# RA6M2 register map
Vendor: Renesas Electronics Corporation; Series: RA6; File version: 1.1
CPU: CM4 r0p1, little endian, MPU, FPU, VTOR, 4 interrupt priority bits
Registers are 8-bit, read-write, reset 0x0 unless marked. A register's access mark holds for its fields unless they carry their own. Offsets are from the block's base; [hi:lo] are bit positions; {n}, {i} and the like mark numbered series; 'fields as' and 'values as' point back to an identical list; <NAME> marks a mode.

## GPT32EH0 (part 2 of 2) — General PWM Timer 0 (32-bit Enhanced High Resolution)
Base 0x40078000
Same registers: GPT32EH1 0x40078100, GPT32EH2 0x40078200, GPT32EH3 0x40078300, GPT32E4 0x40078400, GPT32E5 0x40078500, GPT32E6 0x40078600, GPT32E7 0x40078700
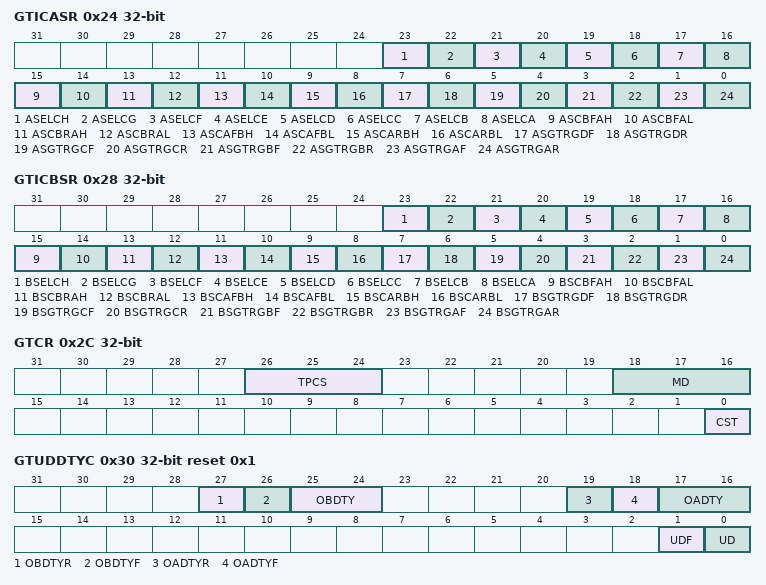
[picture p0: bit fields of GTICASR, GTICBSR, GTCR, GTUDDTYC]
0x24 GTICASR 32-bit — General PWM Timer Input Capture Source Select Register A
  [23] ASELCH — ELC_GPTH Event Source GTCCRA Input Capture Enable
    0=Disable GTCCRA input capture on ELC_GPTH input; 1=Enable GTCCRA input capture on ELC_GPTH input
  [22] ASELCG — ELC_GPTG Event Source GTCCRA Input Capture Enable
    0=Disable GTCCRA input capture on ELC_GPTG input; 1=Enable GTCCRA input capture on ELC_GPTG input
  [21] ASELCF — ELC_GPTF Event Source GTCCRA Input Capture Enable
    0=Disable GTCCRA input capture on ELC_GPTF input; 1=Enable GTCCRA input capture on ELC_GPTF input
  [20] ASELCE — ELC_GPTE Event Source GTCCRA Input Capture Enable
    0=Disable GTCCRA input capture on ELC_GPTE input; 1=Enable GTCCRA input capture on ELC_GPTE input
  [19] ASELCD — ELC_GPTD Event Source GTCCRA Input Capture Enable
    0=Disable GTCCRA input capture on ELC_GPTD input; 1=Enable GTCCRA input capture on ELC_GPTD input
  [18] ASELCC — ELC_GPTC Event Source GTCCRA Input Capture Enable
    0=Disable GTCCRA input capture on ELC_GPTC input; 1=Enable GTCCRA input capture on ELC_GPTC input
  [17] ASELCB — ELC_GPTB Event Source GTCCRA Input Capture Enable
    0=Disable GTCCRA input capture on ELC_GPTB input; 1=Enable GTCCRA input capture on ELC_GPTB input
  [16] ASELCA — ELC_GPTA Event Source GTCCRA Input Capture Enable
    0=Disable GTCCRA input capture on ELC_GPTA input; 1=Enable GTCCRA input capture on ELC_GPTA input
  [15] ASCBFAH — GTIOCB Pin Falling Input during GTIOCA Value High Source GTCCRA Input Capture Enable
    0=Disable GTCCRA input capture on the falling edge of GTIOCB input when GTIOCA input is 1; 1=Enable GTCCRA input capture on the falling edge of GTIOCB input when GTIOCA input is 1
  [14] ASCBFAL — GTIOCB Pin Falling Input during GTIOCA Value Low Source GTCCRA Input Capture Enable
    0=Disable GTCCRA input capture on the falling edge of GTIOCB input when GTIOCA input is 0; 1=Enable GTCCRA input capture on the falling edge of GTIOCB input when GTIOCA input is 0
  [13] ASCBRAH — GTIOCB Pin Rising Input during GTIOCA Value High Source GTCCRA Input Capture Enable
    0=Disable GTCCRA input capture on the rising edge of GTIOCB input when GTIOCA input is 1; 1=Enable GTCCRA input capture on the rising edge of GTIOCB input when GTIOCA input is 1
  [12] ASCBRAL — GTIOCB Pin Rising Input during GTIOCA Value Low Source GTCCRA Input Capture Enable
    0=Disable GTCCRA input capture on the rising edge of GTIOCB input when GTIOCA input is 0; 1=Enable GTCCRA input capture on the rising edge of GTIOCB input when GTIOCA input is 0
  [11] ASCAFBH — GTIOCA Pin Falling Input during GTIOCB Value High Source GTCCRA Input Capture Enable
    0=Disable GTCCRA input capture on the falling edge of GTIOCA input when GTIOCB input is 1; 1=Enable GTCCRA input capture on the falling edge of GTIOCA input when GTIOCB input is 1
  [10] ASCAFBL — GTIOCA Pin Falling Input during GTIOCB Value Low Source GTCCRA Input Capture Enable
    0=Disable GTCCRA input capture on the falling edge of GTIOCA input when GTIOCB input is 0; 1=Enable GTCCRA input capture on the falling edge of GTIOCA input when GTIOCB input is 0
  [9] ASCARBH — GTIOCA Pin Rising Input during GTIOCB Value High Source GTCCRA Input Capture Enable
    0=Disable GTCCRA input capture on the rising edge of GTIOCA input when GTIOCB input is 1; 1=Enable GTCCRA input capture on the rising edge of GTIOCA input when GTIOCB input is 1
  [8] ASCARBL — GTIOCA Pin Rising Input during GTIOCB Value Low Source GTCCRA Input Capture Enable
    0=Disable GTCCRA input capture on the rising edge of GTIOCA input when GTIOCB input is 0; 1=Enable GTCCRA input capture on the rising edge of GTIOCA input when GTIOCB input is 0
  [7] ASGTRGDF — GTETRGD Pin Falling Input Source GTCCRA Input Capture Enable
    0=Disable GTCCRA input capture on the falling edge of GTETRGD input; 1=Enable GTCCRA input capture on the falling edge of GTETRGD input
  [6] ASGTRGDR — GTETRGD Pin Rising Input Source GTCCRA Input Capture Enable
    0=Disable GTCCRA input capture on the rising edge of GTETRGD input; 1=Enable GTCCRA input capture on the rising edge of GTETRGD input
  [5] ASGTRGCF — GTETRGC Pin Falling Input Source GTCCRA Input Capture Enable
    0=Disable GTCCRA input capture on the falling edge of GTETRGC input; 1=Enable GTCCRA input capture on the falling edge of GTETRGC input
  [4] ASGTRGCR — GTETRGC Pin Rising Input Source GTCCRA Input Capture Enable
    0=Disable GTCCRA input capture on the rising edge of GTETRGC input; 1=Enable GTCCRA input capture on the rising edge of GTETRGC input
  [3] ASGTRGBF — GTETRGB Pin Falling Input Source GTCCRA Input Capture Enable
    0=Disable GTCCRA input capture on the falling edge of GTETRGB input; 1=Enable GTCCRA input capture on the falling edge of GTETRGB input
  [2] ASGTRGBR — GTETRGB Pin Rising Input Source GTCCRA Input Capture Enable
    0=Disable GTCCRA input capture on the rising edge of GTETRGB input; 1=Enable GTCCRA input capture on the rising edge of GTETRGB input
  [1] ASGTRGAF — GTETRGA Pin Falling Input Source GTCCRA Input Capture Enable
    0=Disable GTCCRA input capture on the falling edge of GTETRGA input; 1=Enable GTCCRA input capture on the falling edge of GTETRGA input
  [0] ASGTRGAR — GTETRGA Pin Rising Input Source GTCCRA Input Capture Enable
    0=Disable GTCCRA input capture on the rising edge of GTETRGA input; 1=Enable GTCCRA input capture on the rising edge of GTETRGA input
0x28 GTICBSR 32-bit — General PWM Timer Input Capture Source Select Register B
  [23] BSELCH — ELC_GPTH Event Source GTCCRB Input Capture Enable
    0=Disable GTCCRB input capture on ELC_GPTH input; 1=Enable GTCCRB input capture on ELC_GPTH input
  [22] BSELCG — ELC_GPTG Event Source GTCCRB Input Capture Enable
    0=Disable GTCCRB input capture on ELC_GPTG input; 1=Enable GTCCRB input capture on ELC_GPTG input
  [21] BSELCF — ELC_GPTF Event Source GTCCRB Input Capture Enable
    0=Disable GTCCRB input capture on ELC_GPTF input; 1=Enable GTCCRB input capture on ELC_GPTF input
  [20] BSELCE — ELC_GPTE Event Source GTCCRB Input Capture Enable
    0=Disable GTCCRB input capture on ELC_GPTE input; 1=Enable GTCCRB input capture on ELC_GPTE input
  [19] BSELCD — ELC_GPTD Event Source GTCCRB Input Capture Enable
    0=Disable GTCCRB input capture on ELC_GPTD input; 1=Enable GTCCRB input capture on ELC_GPTD input
  [18] BSELCC — ELC_GPTC Event Source GTCCRB Input Capture Enable
    0=Disable GTCCRB input capture on ELC_GPTC input; 1=Enable GTCCRB input capture on ELC_GPTC input
  [17] BSELCB — ELC_GPTB Event Source GTCCRB Input Capture Enable
    0=Disable GTCCRB input capture on ELC_GPTB input; 1=Enable GTCCRB input capture on ELC_GPTB input
  [16] BSELCA — ELC_GPTA Event Source GTCCRB Input Capture Enable
    0=Disable GTCCRB input capture on ELC_GPTA input; 1=Enable GTCCRB input capture on ELC_GPTA input
  [15] BSCBFAH — GTIOCB Pin Falling Input during GTIOCA Value High Source GTCCRB Input Capture Enable
    0=Disable GTCCRB input capture on the falling edge of GTIOCB input when GTIOCA input is 1; 1=Enable GTCCRB input capture on the falling edge of GTIOCB input when GTIOCA input is 1
  [14] BSCBFAL — GTIOCB Pin Falling Input during GTIOCA Value Low Source GTCCRB Input Capture Enable
    0=Disable GTCCRB input capture on the falling edge of GTIOCB input when GTIOCA input is 0; 1=Enable GTCCRB input capture on the falling edge of GTIOCB input when GTIOCA input is 0
  [13] BSCBRAH — GTIOCB Pin Rising Input during GTIOCA Value High Source GTCCRB Input Capture Enable
    0=Disable GTCCRB input capture on the rising edge of GTIOCB input when GTIOCA input is 1; 1=Enable GTCCRB input capture on the rising edge of GTIOCB input when GTIOCA input is 1
  [12] BSCBRAL — GTIOCB Pin Rising Input during GTIOCA Value Low Source GTCCRB Input Capture Enable
    0=Disable GTCCRB input capture on the rising edge of GTIOCB input when GTIOCA input is 0; 1=Enable GTCCRB input capture on the rising edge of GTIOCB input when GTIOCA input is 0
  [11] BSCAFBH — GTIOCA Pin Falling Input during GTIOCB Value High Source GTCCRB Input Capture Enable
    0=Disable GTCCRB input capture on the falling edge of GTIOCA input when GTIOCB input is 1; 1=Enable GTCCRB input capture on the falling edge of GTIOCA input when GTIOCB input is 1
  [10] BSCAFBL — GTIOCA Pin Falling Input during GTIOCB Value Low Source GTCCRB Input Capture Enable
    0=Disable GTCCRB input capture on the falling edge of GTIOCA input when GTIOCB input is 0; 1=Enable GTCCRB input capture on the falling edge of GTIOCA input when GTIOCB input is 0
  [9] BSCARBH — GTIOCA Pin Rising Input during GTIOCB Value High Source GTCCRB Input Capture Enable
    0=Disable GTCCRB input capture on the rising edge of GTIOCA input when GTIOCB input is 1; 1=Enable GTCCRB input capture on the rising edge of GTIOCA input when GTIOCB input is 1
  [8] BSCARBL — GTIOCA Pin Rising Input during GTIOCB Value Low Source GTCCRB Input Capture Enable
    0=Disable GTCCRB input capture on the rising edge of GTIOCA input when GTIOCB input is 0; 1=Enable GTCCRB input capture on the rising edge of GTIOCA input when GTIOCB input is 0
  [7] BSGTRGDF — GTETRGD Pin Falling Input Source GTCCRB Input Capture Enable
    0=Disable GTCCRB input capture on the falling edge of GTETRGD input; 1=Enable GTCCRB input capture on the falling edge of GTETRGD input
  [6] BSGTRGDR — GTETRGD Pin Rising Input Source GTCCRB Input Capture Enable
    0=Disable GTCCRB input capture on the rising edge of GTETRGD input; 1=Enable GTCCRB input capture on the rising edge of GTETRGD input
  [5] BSGTRGCF — GTETRGC Pin Falling Input Source GTCCRB Input Capture Enable
    0=Disable GTCCRB input capture on the falling edge of GTETRGC input; 1=Enable GTCCRB input capture on the falling edge of GTETRGC input
  [4] BSGTRGCR — GTETRGC Pin Rising Input Source GTCCRB Input Capture Enable
    0=Disable GTCCRB input capture on the rising edge of GTETRGC input; 1=Enable GTCCRB input capture on the rising edge of GTETRGC input
  [3] BSGTRGBF — GTETRGB Pin Falling Input Source GTCCRB Input Capture Enable
    0=Disable GTCCRB input capture on the falling edge of GTETRGB input; 1=Enable GTCCRB input capture on the falling edge of GTETRGB input
  [2] BSGTRGBR — GTETRGB Pin Rising Input Source GTCCRB Input Capture Enable
    0=Disable GTCCRB input capture on the rising edge of GTETRGB input; 1=Enable GTCCRB input capture on the rising edge of GTETRGB input
  [1] BSGTRGAF — GTETRGA Pin Falling Input Source GTCCRB Input Capture Enable
    0=Disable GTCCRB input capture on the falling edge of GTETRGA input; 1=Enable GTCCRB input capture on the falling edge of GTETRGA input
  [0] BSGTRGAR — GTETRGA Pin Rising Input Source GTCCRB Input Capture Enable
    0=Disable GTCCRB input capture on the rising edge of GTETRGA input; 1=Enable GTCCRB input capture on the rising edge of GTETRGA input
0x2C GTCR 32-bit — General PWM Timer Control Register
  [26:24] TPCS — Timer Prescaler Select
    0=PCLK/1; 1=PCLK/4; 2=PCLK/16; 3=PCLK/64; 4=PCLK/256; 5=PCLK/1024; other=others (Setting prohibited)
  [18:16] MD — Mode Select
    0=Saw-wave PWM mode (single buffer or double buffer possible); 1=Saw-wave one-shot pulse mode (fixed buffer operation); 2=Setting prohibited; 3=Setting prohibited; 4=Triangle-wave PWM mode 1 (32-bit transfer at crest) (single buffer or double buffer possible); 5=Triangle-wave PWM mode 2 (32-bit transfer at crest and trough) (single buffer or double buffer possible); 6=Triangle-wave PWM mode 3 (64-bit transfer at trough) fixed buffer operation); 7=Setting prohibited
  [0] CST — Count Start
    0=Count operation is stopped; 1=Count operation is performed
0x30 GTUDDTYC 32-bit reset 0x1 — General PWM Timer Count Direction and Duty Setting Register
  [27] OBDTYR — GTIOCB Output Value Selecting after Releasing 0 percent/100 percent Duty Setting
    0=Apply output value set in 0 percent/100 percent duty to GTIOB[3:2] function after releasing 0percent/100percent duty setting; 1=Apply masked compare match output value to GTIOB[3:2] function after releasing 0percent/100percent duty setting
  [26] OBDTYF — Forcible GTIOCB Output Duty Setting
    0=Do not force setting; 1=Force setting
  [25:24] OBDTY — GTIOCB Output Duty Setting
    0=GTIOCB pin duty is depend on compare match; 1=GTIOCB pin duty is depend on compare match; 2=GTIOCB pin duty 0percent; 3=GTIOCB pin duty 100percent
  [19] OADTYR — GTIOCA Output Value Selecting after Releasing 0 percent/100 percent Duty Setting
    0=Apply output value set in 0 percent/100 percent duty to GTIOA[3:2] function after releasing 0 percent/100 percent duty setting; 1=Apply masked compare match output value to GTIOA[3:2] function after releasing 0 percent/100 percent duty setting
  [18] OADTYF — Forcible GTIOCA Output Duty Setting
    0=Do not force setting; 1=Force setting
  [17:16] OADTY — GTIOCA Output Duty Setting
    0=GTIOCA pin duty is depend on compare match; 1=GTIOCA pin duty is depend on compare match; 2=GTIOCA pin duty 0 percent; 3=GTIOCA pin duty 100 percent
  [1] UDF — Forcible Count Direction Setting
    0=Do not force setting; 1=Force setting
  [0] UD — Count Direction Setting
    0=Count down on GTCNT; 1=Counts up on GTCNT
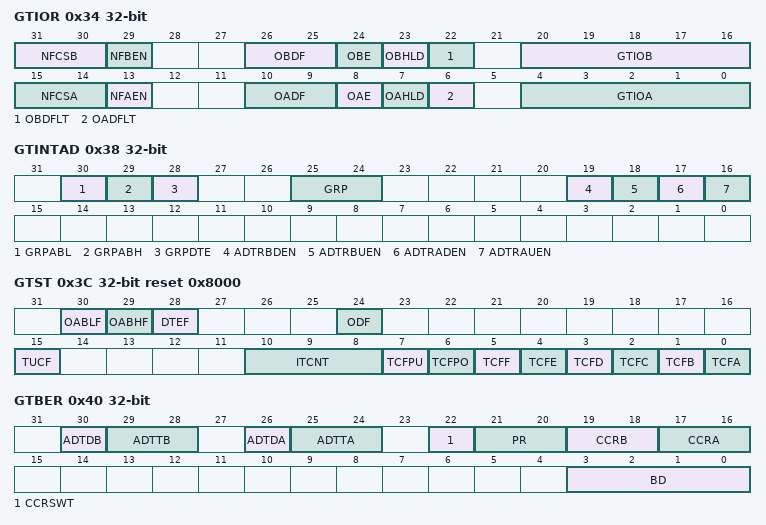
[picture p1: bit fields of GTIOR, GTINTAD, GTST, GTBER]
0x34 GTIOR 32-bit — General PWM Timer I/O Control Register
  [31:30] NFCSB — Noise Filter B Sampling Clock Select
    0=PCLK/1; 1=PCLK/4; 2=PCLK/16; 3=PCLK/64
  [29] NFBEN — Noise Filter B Enable
    0=Disable noise filter for GTIOCB pin; 1=Enable noise filter for GTIOCB pin
  [26:25] OBDF — GTIOCB Pin Disable Value Setting
    0=Prohibit output disable; 1=Set GTIOCB pin to Hi-Z on output disable; 2=Set GTIOCB pin to 0 on output disable; 3=Set GTIOCB pin to 1 on output disable
  [24] OBE — GTIOCB Pin Output Enable
    0=Disable output; 1=Enable output
  [23] OBHLD — GTIOCB Pin Output Setting at the Start/Stop Count
    0=Set GTIOCB pin output level on counting start and stop based on the register setting; 1=Retain GTIOCB pin output level on counting start and stop
  [22] OBDFLT — GTIOCB Pin Output Value Setting at the Count Stop
    0=Output low on GTIOCB pin when counting stops; 1=Output high on GTIOCB pin when counting stops
  [20:16] GTIOB — GTIOCB Pin Function Select
    0=Initial output is Low. Output retained at cycle end. Output retained at GTCCRB compare match.; 1=Initial output is Low. Output retained at cycle end. Low output at GTCCRB compare match.; 2=Initial output is Low. Output retained at cycle end. High output at GTCCRB compare match.; 3=Initial output is Low. Output retained at cycle end. Output toggled at GTCCRB compare match.; 4=Initial output is Low. Low output at cycle end. Output retained at GTCCRB compare match.; 5=Initial output is Low. Low output at cycle end. Low output at GTCCRB compare match.; 6=Initial output is Low. Low output at cycle end. High output at GTCCRB compare match.; 7=Initial output is Low. Low output at cycle end. Output toggled at GTCCRB compare match.; 8=Initial output is Low. High output at cycle end. Output retained at GTCCRB compare match.; 9=Initial output is Low. High output at cycle end. Low output at GTCCRB compare match.; 10=Initial output is Low. High output at cycle end. High output at GTCCRB compare match.; 11=Initial output is Low. High output at cycle end. Output toggled at GTCCRB compare match.; 12=Initial output is Low. Output toggled at cycle end. Output retained at GTCCRB compare match.; 13=Initial output is Low. Output toggled at cycle end. Low output at GTCCRB compare match.; 14=Initial output is Low. Output toggled at cycle end. High output at GTCCRB compare match.; 15=Initial output is Low. Output toggled at cycle end. Output toggled at GTCCRB compare match.; 16=Initial output is High. Output retained at cycle end. Output retained at GTCCRB compare match.; 17=Initial output is High. Output retained at cycle end. Low output at GTCCRB compare match.; 18=Initial output is High. Output retained at cycle end. High output at GTCCRB compare match.; 19=Initial output is High. Output retained at cycle end. Output toggled at GTCCRB compare match.; 20=Initial output is High. Low output at cycle end. Output retained at GTCCRB compare match.; 21=Initial output is High. Low output at cycle end. Low output at GTCCRB compare match.; 22=Initial output is High. Low output at cycle end. High output at GTCCRB compare match.; 23=Initial output is High. Low output at cycle end. Output toggled at GTCCRB compare match.; 24=Initial output is High. High output at cycle end. Output retained at GTCCRB compare match.; 25=Initial output is High. High output at cycle end. Low output at GTCCRB compare match.; 26=Initial output is High. High output at cycle end. High output at GTCCRB compare match.; 27=Initial output is High. High output at cycle end. Output toggled at GTCCRB compare match.; 28=Initial output is High. Output toggled at cycle end. Output retained at GTCCRB compare match.; 29=Initial output is High. Output toggled at cycle end. Low output at GTCCRB compare match.; 30=Initial output is High. Output toggled at cycle end. High output at GTCCRB compare match.; 31=Initial output is High. Output toggled at cycle end. Output toggled at GTCCRB compare match.
  [15:14] NFCSA — Noise Filter A Sampling Clock Select
    0=PCLK/1; 1=PCLK/4; 2=PCLK/16; 3=PCLK/64
  [13] NFAEN — Noise Filter A Enable
    0=Disable noise filter for GTIOCA pin; 1=Enable noise filter for GTIOCA pin
  [10:9] OADF — GTIOCA Pin Disable Value Setting
    0=Prohibit output disable; 1=Set GTIOCA pin to Hi-Z on output disable; 2=Set GTIOCA pin to 0 on output disable; 3=Set GTIOCA pin to 1 on output disable
  [8] OAE — GTIOCA Pin Output Enable
    0=Disable output; 1=Enable output
  [7] OAHLD — GTIOCA Pin Output Setting at the Start/Stop Count
    0=Set GTIOCA pin output level on counting start and stop based on the register setting; 1=Retain GTIOCA pin output level on counting start and stop
  [6] OADFLT — GTIOCA Pin Output Value Setting at the Count Stop
    0=Output low on GTIOCA pin when counting stops; 1=Output high on GTIOCA pin when counting stops
  [4:0] GTIOA — GTIOCA Pin Function Select
    0=Initial output is Low. Output retained at cycle end. Output retained at GTCCRA compare match.; 1=Initial output is Low. Output retained at cycle end. Low output at GTCCRA compare match.; 2=Initial output is Low. Output retained at cycle end. High output at GTCCRA compare match.; 3=Initial output is Low. Output retained at cycle end. Output toggled at GTCCRA compare match.; 4=Initial output is Low. Low output at cycle end. Output retained at GTCCRA compare match.; 5=Initial output is Low. Low output at cycle end. Low output at GTCCRA compare match.; 6=Initial output is Low. Low output at cycle end. High output at GTCCRA compare match.; 7=Initial output is Low. Low output at cycle end. Output toggled at GTCCRA compare match.; 8=Initial output is Low. High output at cycle end. Output retained at GTCCRA compare match.; 9=Initial output is Low. High output at cycle end. Low output at GTCCRA compare match.; 10=Initial output is Low. High output at cycle end. High output at GTCCRA compare match.; 11=Initial output is Low. High output at cycle end. Output toggled at GTCCRA compare match.; 12=Initial output is Low. Output toggled at cycle end. Output retained at GTCCRA compare match.; 13=Initial output is Low. Output toggled at cycle end. Low output at GTCCRA compare match.; 14=Initial output is Low. Output toggled at cycle end. High output at GTCCRA compare match.; 15=Initial output is Low. Output toggled at cycle end. Output toggled at GTCCRA compare match.; 16=Initial output is High. Output retained at cycle end. Output retained at GTCCRA compare match.; 17=Initial output is High. Output retained at cycle end. Low output at GTCCRA compare match.; 18=Initial output is High. Output retained at cycle end. High output at GTCCRA compare match.; 19=Initial output is High. Output retained at cycle end. Output toggled at GTCCRA compare match.; 20=Initial output is High. Low output at cycle end. Output retained at GTCCRA compare match.; 21=Initial output is High. Low output at cycle end. Low output at GTCCRA compare match.; 22=Initial output is High. Low output at cycle end. High output at GTCCRA compare match.; 23=Initial output is High. Low output at cycle end. Output toggled at GTCCRA compare match.; 24=Initial output is High. High output at cycle end. Output retained at GTCCRA compare match.; 25=Initial output is High. High output at cycle end. Low output at GTCCRA compare match.; 26=Initial output is High. High output at cycle end. High output at GTCCRA compare match.; 27=Initial output is High. High output at cycle end. Output toggled at GTCCRA compare match.; 28=Initial output is High. Output toggled at cycle end. Output retained at GTCCRA compare match.; 29=Initial output is High. Output toggled at cycle end. Low output at GTCCRA compare match.; 30=Initial output is High. Output toggled at cycle end. High output at GTCCRA compare match.; 31=Initial output is High. Output toggled at cycle end. Output toggled at GTCCRA compare match.
0x38 GTINTAD 32-bit — General PWM Timer Interrupt Output Setting Register
  [30] GRPABL — Same Time Output Level Low Disable Request Enable
    0=Disable same time output level low disable request; 1=Enable same time output level low disable request
  [29] GRPABH — Same Time Output Level High Disable Request Enable
    0=Disable same time output level high disable request; 1=Enable same time output level high disable request
  [28] GRPDTE — Dead Time Error Output Disable Request Enable
    0=Disable dead time error output disable request; 1=Enable dead time error output disable request
  [25:24] GRP — Output Disable Source Select
    0=Select Group A output disable request; 1=Select Group B output disable request; 2=Select Group C output disable request; 3=Select Group D output disable request
  [19] ADTRBDEN — GTADTRB Compare Match (Down-Counting) A/D Converter Start Request Interrupt Enable
    0=Disable A/D converter start request; 1=Enable A/D converter start request
  [18] ADTRBUEN — GTADTRB Compare Match (Up-Counting) A/D Converter Start Request Interrupt Enable
    values as ADTRBDEN
  [17] ADTRADEN — GTADTRA Compare Match (Down-Counting) A/D Converter Start Request Interrupt Enable
    values as ADTRBDEN
  [16] ADTRAUEN — GTADTRA Compare Match (Up-Counting) A/D Converter Start Request Interrupt Enable
    values as ADTRBDEN
0x3C GTST 32-bit reset 0x8000 — General PWM Timer Status Register
  [30] OABLF ro — Same Time Output Level Low Disable Request Enable
    0=GTIOCA pin and GTIOCB pin don't output 0 at the same time; 1=GTIOCA pin and GTIOCB pin output 0 at the same time
  [29] OABHF ro — Same Time Output Level High Disable Request Enable
    0=GTIOCA pin and GTIOCB pin don't output 1 at the same time; 1=GTIOCA pin and GTIOCB pin output 1 at the same time
  [28] DTEF ro — Dead Time Error Flag
    0=No dead time error has occurred; 1=A dead time error has occurred
  [24] ODF ro — Output Disable Flag
    0=No output disable request is generated; 1=An output disable request is generated
  [15] TUCF ro — Count Direction Flag
    0=GTCNT counter is counting down; 1=GTCNT counter is counting up
  [10:8] ITCNT ro — GTCIV/GTCIU Interrupt Skipping Count Counter(Counter for counting the number of times a timer interrupt has been skipped.)
  [7] TCFPU — Underflow Flag
    0=No underflow (trough) has occurred; 1=An underflow (trough) has occurred
  [6] TCFPO — Overflow Flag
    0=No overflow (crest) has occurred; 1=An overflow (crest) has occurred
  [5] TCFF — Input Compare Match Flag F
    0=No compare match of GTCCRF is generated; 1=A compare match of GTCCRF is generated
  [4] TCFE — Input Compare Match Flag E
    0=No compare match of GTCCRE is generated; 1=A compare match of GTCCRE is generated
  [3] TCFD — Input Compare Match Flag D
    0=No compare match of GTCCRD is generated; 1=A compare match of GTCCRD is generated
  [2] TCFC — Input Compare Match Flag C
    0=No compare match of GTCCRC is generated; 1=A compare match of GTCCRC is generated
  [1] TCFB — Input Capture/Compare Match Flag B
    0=No input capture/compare match of GTCCRB is generated; 1=An input capture/compare match of GTCCRB is generated
  [0] TCFA — Input Capture/Compare Match Flag A
    0=No input capture/compare match of GTCCRA is generated; 1=An input capture/compare match of GTCCRA is generated
0x40 GTBER 32-bit — General PWM Timer Buffer Enable Register
  [30] ADTDB — GTADTRB Double Buffer Operation
    0=Single buffer operation (GTADTBRB --> GTADTRB); 1=Double buffer operation (GTADTDBRB --> GTADTBRB --> GTADTDRB)
  [29:28] ADTTB — GTADTRB Buffer Transfer Timing Select in the Triangle wavesNOTE: In the Saw waves, values other than 0 0: Transfer at an underflow (in down-counting) or overflow (in up-counting) is performed.
    0=No transfer; 1=Transfer at crest; 2=Transfer at trough; 3=Transfer at both crest and trough
  [26] ADTDA — GTADTRA Double Buffer Operation
    0=Single buffer operation (GTADTBRA --> GTADTRA); 1=Double buffer operation (GTADTDBRA --> GTADTBRA --> GTADTDRA)
  [25:24] ADTTA — GTADTRA Buffer Transfer Timing Select in the Triangle wavesNOTE: In the Saw waves, values other than 0 0: Transfer at an underflow (in down-counting) or overflow (in up-counting) is performed.
    values as ADTTB
  [22] CCRSWT wo — GTCCRA and GTCCRB Forcible Buffer OperationThis bit is read as 0.
    0=no effect; 1=Forcibly performs buffer transfer of GTCCRA and GTCCRB. This bit automatically returns to 0 after the writing of 1.
  [21:20] PR — GTPR Buffer Operation
    0=Buffer operation is not performed; 1=Single buffer operation (GTPBR --> GTPR); 2=Double buffer operation (GTPDBR --> GTPBR --> GTPR); 3=Double buffer operation (GTPDBR --> GTPBR --> GTPR)
  [19:18] CCRB — GTCCRB Buffer Operation
    0=Buffer operation is not performed; 1=Single buffer operation (GTCCRB <--> GTCCRE); 2=Double buffer operation (GTCCRB <--> GTCCRE <--> GTCCRF); 3=Double buffer operation (GTCCRB <--> GTCCRE <--> GTCCRF)
  [17:16] CCRA — GTCCRA Buffer Operation
    0=Buffer operation is not performed; 1=Single buffer operation (GTCCRA <--> GTCCRC); 2=Double buffer operation (GTCCRA <--> GTCCRC <--> GTCCRD); 3=Double buffer operation (GTCCRA <--> GTCCRC <--> GTCCRD)
  [3:0] BD — BD[3]: GTDV Buffer Operation DisableBD[2]: GTADTR Buffer Operation DisableBD[1]: GTPR Buffer Operation DisableBD[0]: GTCCR Buffer Operation Disable
    0=Enable buffer operation; 1=Disable buffer operation
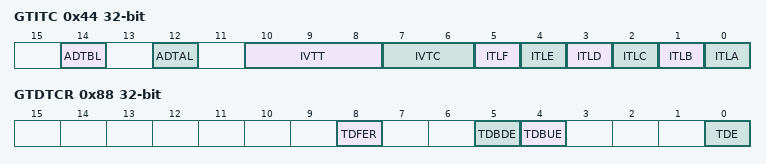
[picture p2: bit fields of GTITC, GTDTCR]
0x44 GTITC 32-bit — General PWM Timer Interrupt and A/D Converter Start Request Skipping Setting Register
  [14] ADTBL — GTADTRB A/D Converter Start Request Link
    0=Do not link with GPTn_OVF/GPTn_UDF interrupt skipping function; 1=Link with GPTn_OVF/GPTn_UDF interrupt skipping function
  [12] ADTAL — GTADTRA A/D Converter Start Request Link
    values as ADTBL
  [10:8] IVTT — GPT_OVF/GPT_UDF Interrupt Skipping Count Select
    0=No skipping; {v}=Skipping count of {v} (v=1..7)
  [7:6] IVTC — GPT_OVF/GPT_UDF Interrupt Skipping Function Select
    0=Do not perform skipping; 1=Count and skip both overflow and underflow for saw waves and crest for triangle waves; 2=Count and skip both overflow and underflow for saw waves and trough for triangle waves; 3=Count and skip both overflow and underflow for saw waves and both crest and trough for triangle waves
  [5] ITLF — GTCCRF Compare Match Interrupt Link
    values as ADTBL
  [4] ITLE — GTCCRE Compare Match Interrupt Link
    values as ADTBL
  [3] ITLD — GTCCRD Compare Match Interrupt Link
    values as ADTBL
  [2] ITLC — GTCCRC Compare Match Interrupt Link
    values as ADTBL
  [1] ITLB — GTCCRB Compare Match/Input Capture Interrupt Link
    values as ADTBL
  [0] ITLA — GTCCRA Compare Match/Input Capture Interrupt Link
    values as ADTBL
0x48 GTCNT 32-bit — General PWM Timer Counter
  [31:0] GTCNT — Counter
0x4C GTCCRA 32-bit reset 0xFFFFFFFF — General PWM Timer Compare Capture Register A
  [31:0] GTCCRA — Compare Capture Register A
0x50 GTCCRB 32-bit reset 0xFFFFFFFF — General PWM Timer Compare Capture Register B
  [31:0] GTCCRB — Compare Capture Register B
0x54 GTCCRC 32-bit reset 0xFFFFFFFF — General PWM Timer Compare Capture Register C
  [31:0] GTCCRC — Compare Capture Register C
0x58 GTCCRE 32-bit reset 0xFFFFFFFF — General PWM Timer Compare Capture Register E
  [31:0] GTCCRE — Compare Capture Register E
0x5C GTCCRD 32-bit reset 0xFFFFFFFF — General PWM Timer Compare Capture Register D
  [31:0] GTCCRD — Compare Capture Register D
0x60 GTCCRF 32-bit reset 0xFFFFFFFF — General PWM Timer Compare Capture Register F
  [31:0] GTCCRF — Compare Capture Register F
0x64 GTPR 32-bit reset 0xFFFFFFFF — General PWM Timer Cycle Setting Register
  [31:0] GTPR — Cycle Setting Register
0x68 GTPBR 32-bit reset 0xFFFFFFFF — General PWM Timer Cycle Setting Buffer Register
  [31:0] GTPBR — Cycle Setting Buffer Register
0x6C GTPDBR 32-bit reset 0xFFFFFFFF — General PWM Timer Cycle Setting Double-Buffer Register
  [31:0] GTPDBR — Cycle Setting Double-Buffer Register
0x70 GTADTRA 32-bit reset 0xFFFFFFFF — A/D Converter Start Request Timing Register A
0x74 GTADTBRA 32-bit reset 0xFFFFFFFF — A/D Converter Start Request Timing Buffer Register A
0x78 GTADTDBRA 32-bit reset 0xFFFFFFFF — A/D Converter Start Request Timing Double-Buffer Register A
0x7C GTADTRB 32-bit reset 0xFFFFFFFF — A/D Converter Start Request Timing Register B
0x80 GTADTBRB 32-bit reset 0xFFFFFFFF — A/D Converter Start Request Timing Buffer Register B
0x84 GTADTDBRB 32-bit reset 0xFFFFFFFF — A/D Converter Start Request Timing Double-Buffer Register B
0x88 GTDTCR 32-bit — General PWM Timer Dead Time Control Register
  [8] TDFER — GTDVD Setting
    0=Set GTDVU and GTDVD separately; 1=Automatically set the value written to GTDVU to GTDVD
  [5] TDBDE — GTDVD Buffer Operation Enable
    0=Disable GTDVD buffer operation; 1=Enable GTDVD buffer operation
  [4] TDBUE — GTDVU Buffer Operation Enable
    0=Disable GTDVU buffer operation; 1=Enable GTDVU buffer operation
  [0] TDE — Negative-Phase Waveform Setting
    0=Set GTCCRB without using GTDVU and GTDVD; 1=Use GTDVU and GTDVD to set the compare match value for negative-phase waveform with automatic dead time in GTCCRB
0x8C GTDVU 32-bit reset 0xFFFFFFFF — General PWM Timer Dead Time Value Register U
  [31:0] GTDVU — Dead Time Value Register U
0x90 GTDVD 32-bit reset 0xFFFFFFFF — General PWM Timer Dead Time Value Register D
  [31:0] GTDVD — Dead Time Value Register D
0x94 GTDBU 32-bit reset 0xFFFFFFFF — General PWM Timer Dead Time Buffer Register U
  [31:0] GTDVU — Dead Time Buffer Register U
0x98 GTDBD 32-bit reset 0xFFFFFFFF — General PWM Timer Dead Time Buffer Register D
  [31:0] GTDBD — Dead Time Buffer Register D
0x9C GTSOS 32-bit ro — General PWM Timer Output Protection Function Status Register
  [1:0] SOS — Output Protection Function Status
    0=Normal operation; 1=Protected state (GTCCRA = 0 is set during transfer at trough or crest); 2=Protected state (GTCCRA >= GTPR is set during transfer at trough); 3=Protected state (GTCCRA >= GTPR is set during transfer at crest)
0xA0 GTSOTR 32-bit — General PWM Timer Output Protection Function Temporary Release Register
  [0] SOTR — Output Protection Function Temporary Release
    0=Do not release protected state; 1=Release protected state

## GPT328 (part 2 of 2) — General PWM Timer 8 (32-bit Enhanced)
Base 0x40078800
Same registers: GPT329 0x40078900, GPT3210 0x40078A00, GPT3211 0x40078B00, GPT3212 0x40078C00, GPT3213 0x40078D00
Registers as GPT32EH0, without GTITC, GTPDBR, GTADTRA, GTADTBRA, GTADTDBRA, GTADTRB, GTADTBRB, GTADTDBRB, GTDVD, GTDBU, GTDBD, GTSOS, GTSOTR; these are added or differ:
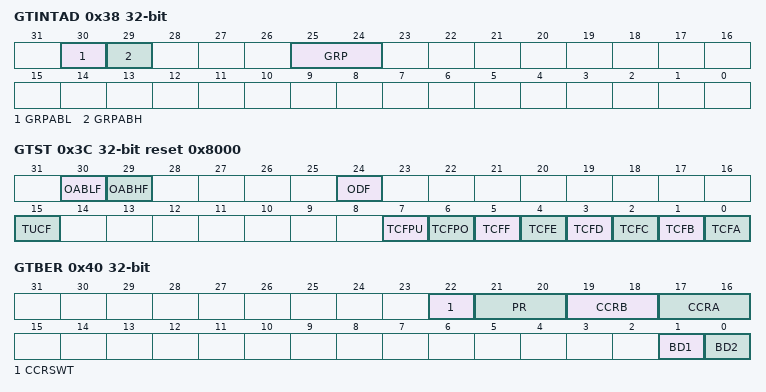
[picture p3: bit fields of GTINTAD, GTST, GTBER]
0x38 GTINTAD 32-bit — General PWM Timer Interrupt Output Setting Register
  [30] GRPABL — Same Time Output Level Low Disable Request Enable
    0=Disable same time output level low disable request; 1=Enable same time output level low disable request
  [29] GRPABH — Same Time Output Level High Disable Request Enable
    0=Disable same time output level high disable request; 1=Enable same time output level high disable request
  [25:24] GRP — Output Disable Source Select
    0=Select Group A output disable request; 1=Select Group B output disable request; 2=Select Group C output disable request; 3=Select Group D output disable request
0x3C GTST 32-bit reset 0x8000 — General PWM Timer Status Register
  [30] OABLF ro — Same Time Output Level Low Disable Request Enable
    0=GTIOCA pin and GTIOCB pin don't output 0 at the same time; 1=GTIOCA pin and GTIOCB pin output 0 at the same time
  [29] OABHF ro — Same Time Output Level High Disable Request Enable
    0=GTIOCA pin and GTIOCB pin don't output 1 at the same time; 1=GTIOCA pin and GTIOCB pin output 1 at the same time
  [24] ODF ro — Output Disable Flag
    0=No output disable request is generated; 1=An output disable request is generated
  [15] TUCF ro — Count Direction Flag
    0=GTCNT counter is counting down; 1=GTCNT counter is counting up
  [7] TCFPU — Underflow Flag
    0=No underflow (trough) has occurred; 1=An underflow (trough) has occurred
  [6] TCFPO — Overflow Flag
    0=No overflow (crest) has occurred; 1=An overflow (crest) has occurred
  [5] TCFF — Input Compare Match Flag F
    0=No compare match of GTCCRF is generated; 1=A compare match of GTCCRF is generated
  [4] TCFE — Input Compare Match Flag E
    0=No compare match of GTCCRE is generated; 1=A compare match of GTCCRE is generated
  [3] TCFD — Input Compare Match Flag D
    0=No compare match of GTCCRD is generated; 1=A compare match of GTCCRD is generated
  [2] TCFC — Input Compare Match Flag C
    0=No compare match of GTCCRC is generated; 1=A compare match of GTCCRC is generated
  [1] TCFB — Input Capture/Compare Match Flag B
    0=No input capture/compare match of GTCCRB is generated; 1=An input capture/compare match of GTCCRB is generated
  [0] TCFA — Input Capture/Compare Match Flag A
    0=No input capture/compare match of GTCCRA is generated; 1=An input capture/compare match of GTCCRA is generated
0x40 GTBER 32-bit — General PWM Timer Buffer Enable Register
  [22] CCRSWT wo — GTCCRA and GTCCRB Forcible Buffer OperationThis bit is read as 0.
    0=no effect; 1=Forcibly performs buffer transfer of GTCCRA and GTCCRB. This bit automatically returns to 0 after the writing of 1.
  [21:20] PR — GTPR Buffer Operation
    0=Buffer operation is not performed; 1=Single buffer operation (GTPBR --> GTPR); other=others (Setting prohibited)
  [19:18] CCRB — GTCCRB Buffer Operation
    values as GPT32EH0.GTBER.CCRB
  [17:16] CCRA — GTCCRA Buffer Operation
    values as GPT32EH0.GTBER.CCRA
  [1] BD1 — GTPR Buffer Operation Disable
    0=Enable buffer operation; 1=Disable buffer operation
  [0] BD2 — GTCCR Buffer Operation Disable
    0=Enable buffer operation; 1=Disable buffer operation
0x88 GTDTCR 32-bit — General PWM Timer Dead Time Control Register
  [0] TDE — Negative-Phase Waveform Setting
    0=Set GTCCRB without using GTDVU and GTDVD; 1=Use GTDVU and GTDVD to set the compare match value for negative-phase waveform with automatic dead time in GTCCRB
